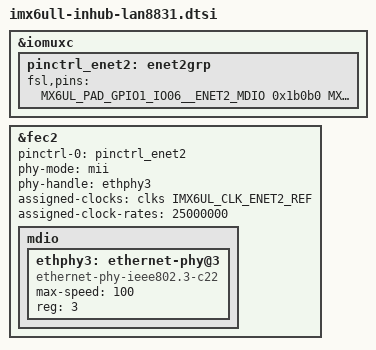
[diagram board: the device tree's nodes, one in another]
// SPDX-License-Identifier: GPL-2.0-only
/*
 * Copyright 2026 in.hub GmbH
 */

/ {
	/delete-node/ regulator-eth-phy;
};

&iomuxc {
	/delete-node/ enet2grp;
	/delete-node/ enet2-sleepgrp;

	pinctrl_enet2: enet2grp {
		fsl,pins = <
			MX6UL_PAD_GPIO1_IO06__ENET2_MDIO	0x1b0b0
			MX6UL_PAD_GPIO1_IO07__ENET2_MDC		0x1b0b0
			MX6UL_PAD_ENET2_RX_DATA0__ENET2_RDATA00	0x1b0b0
			MX6UL_PAD_ENET2_RX_DATA1__ENET2_RDATA01	0x1b0b0
			MX6UL_PAD_UART3_TX_DATA__ENET2_RDATA02	0x1b0b0
			MX6UL_PAD_UART3_RX_DATA__ENET2_RDATA03  0x1b0b0
			MX6UL_PAD_ENET2_RX_EN__ENET2_RX_EN	0x1b0b0
			MX6UL_PAD_ENET2_TX_CLK__ENET2_TX_CLK 0x4001b031
			MX6UL_PAD_ENET2_TX_DATA0__ENET2_TDATA00	0x1b0b0
			MX6UL_PAD_ENET2_TX_DATA1__ENET2_TDATA01	0x1b0b0
			MX6UL_PAD_UART4_TX_DATA__ENET2_TDATA02	0x1b0b0
			MX6UL_PAD_UART4_RX_DATA__ENET2_TDATA03	0x1b0b0
			MX6UL_PAD_ENET2_TX_EN__ENET2_TX_EN	0x1b0b0
			MX6UL_PAD_UART3_CTS_B__ENET2_RX_CLK		0x1b0b0
			MX6UL_PAD_LCD_DATA16__GPIO3_IO21 0x1b0b0
			MX6UL_PAD_ENET2_RX_ER__ENET2_RX_ER	0x1b0b0
			MX6UL_PAD_UART5_RX_DATA__ENET2_COL	0x1b0b0
			MX6UL_PAD_UART5_TX_DATA__ENET2_CRS	0x1b0b0
		>;
	};
};

&fec2 {
	/delete-property/ pinctrl-1;
	/delete-property/ phy-supply;

	pinctrl-names = "default";
	pinctrl-0 = <&pinctrl_enet2>;
	phy-mode = "mii";
	phy-handle = <&ethphy3>;
	status = "okay";
	assigned-clocks = <&clks IMX6UL_CLK_ENET2_REF>;
	assigned-clock-rates = <25000000>;

	mdio {
		#address-cells = <1>;
		#size-cells = <0>;

		/delete-node/ ethernet-phy@2;

		ethphy3: ethernet-phy@3 {
			compatible = "ethernet-phy-ieee802.3-c22";
			max-speed = <100>;
			reg = <3>;
		};
	};
};
